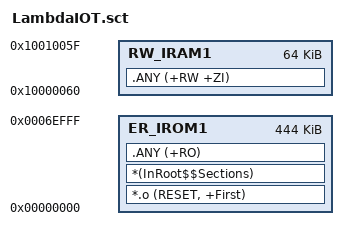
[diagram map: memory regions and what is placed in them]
; *************************************************************
; *** Scatter-Loading Description File generated by uVision ***
; *************************************************************
LR_IROM1 0x00000000 0x0006F000  {    ; load region size_region, for work code
  ER_IROM1 0x00000000 0x0006F000  {  ; load address = execution address
   *.o (RESET, +First)
   *(InRoot$$Sections)
   .ANY (+RO)
  }
  RW_IRAM1 0x10000060 0x00010000  {  ; RW data
   .ANY (+RW +ZI)
  }
;  RW_SDRAM0 0xA0000000 0x01000000  {  ; RW data
;   .ANY (+RW +ZI)	;//for dynamic assign
;  }
}
